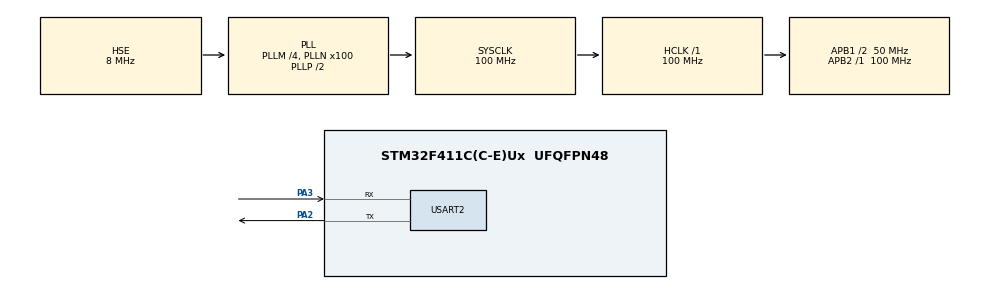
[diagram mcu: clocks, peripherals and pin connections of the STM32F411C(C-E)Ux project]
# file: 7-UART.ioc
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Mcu.Family=STM32F4
Mcu.Name=STM32F411C(C-E)Ux
Mcu.Package=UFQFPN48
NVIC.PriorityGroup=NVIC_PRIORITYGROUP_4
PA2.Mode=Asynchronous
PA2.Signal=USART2_TX
PA3.Mode=Asynchronous
PA3.Signal=USART2_RX
PC14-OSC32_IN.Mode=LSE-External-Oscillator
PC14-OSC32_IN.Signal=RCC_OSC32_IN
PC15-OSC32_OUT.Mode=LSE-External-Oscillator
PC15-OSC32_OUT.Signal=RCC_OSC32_OUT
PH0\ -\ OSC_IN.Mode=HSE-External-Oscillator
PH0\ -\ OSC_IN.Signal=RCC_OSC_IN
PH1\ -\ OSC_OUT.Mode=HSE-External-Oscillator
PH1\ -\ OSC_OUT.Signal=RCC_OSC_OUT
ProjectManager.HeapSize=0x400
ProjectManager.StackSize=0x200
ProjectManager.TargetToolchain=SW4STM32
RCC.48MHZClocksFreq_Value=50000000
RCC.AHBFreq_Value=100000000
RCC.APB1CLKDivider=RCC_HCLK_DIV2
RCC.APB1Freq_Value=50000000
RCC.APB1TimCLKDivider=1
RCC.APB1TimFreq_Value=50000000
RCC.APB2Freq_Value=100000000
RCC.APB2TimFreq_Value=100000000
RCC.CortexFreq_Value=100000000
RCC.HCLKFreq_Value=100000000
RCC.HSE_VALUE=8000000
RCC.HSI_VALUE=16000000
RCC.PLLM=4
RCC.PLLN=100
RCC.PLLSourceVirtual=RCC_PLLSOURCE_HSE
RCC.SYSCLKFreq_VALUE=100000000
RCC.SYSCLKSource=RCC_SYSCLKSOURCE_PLLCLK
RCC.VCOOutputFreq_Value=200000000
board=7-UART

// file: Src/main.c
/**
 ******************************************************************************
 * File Name          : main.c
 * Description        : Main program body
 ******************************************************************************
 *
 * COPYRIGHT(c) 2016 STMicroelectronics
 *
 * Redistribution and use in source and binary forms, with or without modification,
 * are permitted provided that the following conditions are met:
 *   1. Redistributions of source code must retain the above copyright notice,
 *      this list of conditions and the following disclaimer.
 *   2. Redistributions in binary form must reproduce the above copyright notice,
 *      this list of conditions and the following disclaimer in the documentation
 *      and/or other materials provided with the distribution.
 *   3. Neither the name of STMicroelectronics nor the names of its contributors
 *      may be used to endorse or promote products derived from this software
 *      without specific prior written permission.
 *
 * THIS SOFTWARE IS PROVIDED BY THE COPYRIGHT HOLDERS AND CONTRIBUTORS "AS IS"
 * AND ANY EXPRESS OR IMPLIED WARRANTIES, INCLUDING, BUT NOT LIMITED TO, THE
 * IMPLIED WARRANTIES OF MERCHANTABILITY AND FITNESS FOR A PARTICULAR PURPOSE ARE
 * DISCLAIMED. IN NO EVENT SHALL THE COPYRIGHT HOLDER OR CONTRIBUTORS BE LIABLE
 * FOR ANY DIRECT, INDIRECT, INCIDENTAL, SPECIAL, EXEMPLARY, OR CONSEQUENTIAL
 * DAMAGES (INCLUDING, BUT NOT LIMITED TO, PROCUREMENT OF SUBSTITUTE GOODS OR
 * SERVICES; LOSS OF USE, DATA, OR PROFITS; OR BUSINESS INTERRUPTION) HOWEVER
 * CAUSED AND ON ANY THEORY OF LIABILITY, WHETHER IN CONTRACT, STRICT LIABILITY,
 * OR TORT (INCLUDING NEGLIGENCE OR OTHERWISE) ARISING IN ANY WAY OUT OF THE USE
 * OF THIS SOFTWARE, EVEN IF ADVISED OF THE POSSIBILITY OF SUCH DAMAGE.
 *
 ******************************************************************************
 */
#include "stm32f4xx_hal.h"
#include "usart.h"
#include "gpio.h"

/* USER CODE BEGIN PV */
/* Private variables ---------------------------------------------------------*/

/* USER CODE END PV */

void SystemClock_Config(void);

/* USER CODE BEGIN PFP */
/* Private function prototypes -----------------------------------------------*/

/* USER CODE END PFP */

/* USER CODE BEGIN 0 */
void uart_write_line(uint8_t * buffer, uint16_t data_len) {
	*(buffer + data_len++) = '\r';
	*(buffer + data_len++) = '\n';
	HAL_UART_Transmit(&huart2, buffer, data_len, 1);
}

uint16_t uart_read_line(uint8_t * buffer, uint16_t buffer_size) {
	HAL_StatusTypeDef status;
	uint8_t current_char;
	uint16_t char_counter = 0;

	while (1) {
		status = HAL_UART_Receive(&huart2, &current_char, 1, 1);
		if (status == HAL_OK) {
			if (current_char == '\r' || current_char == '\n') {
				if (char_counter == 0)
					continue;
				else
					break;
			}
			*(buffer + char_counter++) = current_char;
		}
	}

	return char_counter;
}
/* USER CODE END 0 */

int main(void) {

	/* MCU Configuration----------------------------------------------------------*/

	/* Reset of all peripherals, Initializes the Flash interface and the Systick. */
	HAL_Init();

	/* Configure the system clock */
	SystemClock_Config();

	/* Initialize all configured peripherals */
	MX_GPIO_Init();
	MX_USART2_UART_Init();

	/* Infinite loop */
	while (1) {

		/* USER CODE BEGIN 3 */
		/*uint8_t buffer[1024], reversed_buffer[1024];
		 HAL_StatusTypeDef status;
		 uint8_t current_char;
		 uint16_t char_counter = 0;

		 for (uint16_t i = 0; i < 1024; i++) {
		 buffer[i] = '\0';
		 reversed_buffer[i] = '\0';
		 }

		 while (1) {
		 status = HAL_UART_Receive(&huart2, &current_char, 1, 1);
		 if (status == HAL_OK) {
		 if (current_char == '\r')
		 break;
		 buffer[char_counter] = current_char;
		 char_counter++;
		 }
		 }

		 for (uint16_t i = 0; i < char_counter; i++)
		 reversed_buffer[i] = buffer[char_counter - 1 - i];
		 reversed_buffer[char_counter] = '\r';
		 char_counter++;

		 HAL_UART_Transmit(&huart2, &reversed_buffer, char_counter, 1);*/

		uint8_t buffer[1024], reversed_buffer[1024];
		uint16_t data_len = 0, buffer_size = 1024;
		data_len = uart_read_line(&buffer, buffer_size);
		for (uint16_t i = 0; i < data_len; i++)
			reversed_buffer[i] = buffer[data_len - 1 - i];
		uart_write_line(&reversed_buffer, data_len);
	}
	/* USER CODE END 3 */
}

/** System Clock Configuration
 */
void SystemClock_Config(void) {

	RCC_OscInitTypeDef RCC_OscInitStruct;
	RCC_ClkInitTypeDef RCC_ClkInitStruct;

	__PWR_CLK_ENABLE()
	;

	__HAL_PWR_VOLTAGESCALING_CONFIG(PWR_REGULATOR_VOLTAGE_SCALE1);

	RCC_OscInitStruct.OscillatorType = RCC_OSCILLATORTYPE_HSE;
	RCC_OscInitStruct.HSEState = RCC_HSE_ON;
	RCC_OscInitStruct.PLL.PLLState = RCC_PLL_ON;
	RCC_OscInitStruct.PLL.PLLSource = RCC_PLLSOURCE_HSE;
	RCC_OscInitStruct.PLL.PLLM = 4;
	RCC_OscInitStruct.PLL.PLLN = 100;
	RCC_OscInitStruct.PLL.PLLP = RCC_PLLP_DIV2;
	RCC_OscInitStruct.PLL.PLLQ = 4;
	HAL_RCC_OscConfig(&RCC_OscInitStruct);

	RCC_ClkInitStruct.ClockType = RCC_CLOCKTYPE_HCLK | RCC_CLOCKTYPE_SYSCLK
			| RCC_CLOCKTYPE_PCLK1 | RCC_CLOCKTYPE_PCLK2;
	RCC_ClkInitStruct.SYSCLKSource = RCC_SYSCLKSOURCE_PLLCLK;
	RCC_ClkInitStruct.AHBCLKDivider = RCC_SYSCLK_DIV1;
	RCC_ClkInitStruct.APB1CLKDivider = RCC_HCLK_DIV2;
	RCC_ClkInitStruct.APB2CLKDivider = RCC_HCLK_DIV1;
	HAL_RCC_ClockConfig(&RCC_ClkInitStruct, FLASH_LATENCY_3);

	HAL_SYSTICK_Config(HAL_RCC_GetHCLKFreq() / 1000);

	HAL_SYSTICK_CLKSourceConfig(SYSTICK_CLKSOURCE_HCLK);

	/* SysTick_IRQn interrupt configuration */
	HAL_NVIC_SetPriority(SysTick_IRQn, 0, 0);
}

/************************ (C) COPYRIGHT STMicroelectronics *****END OF FILE****/
